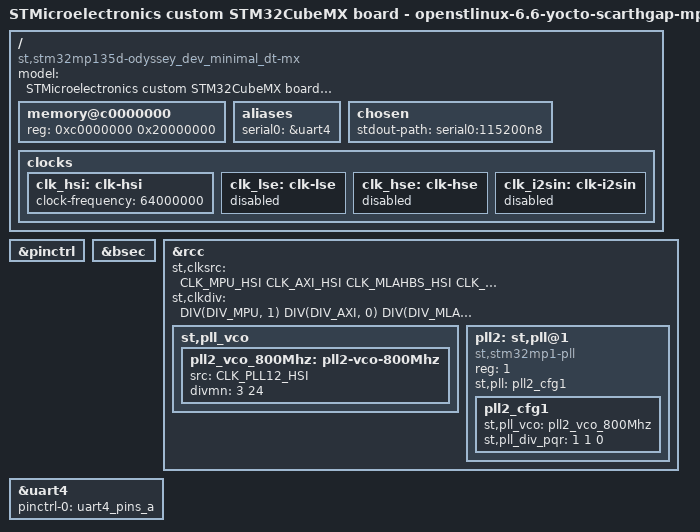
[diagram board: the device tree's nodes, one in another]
// SPDX-License-Identifier: (GPL-2.0+ OR BSD-3-Clause)
/*
 * Copyright (C) 2026, STMicroelectronics - All Rights Reserved
 * Author: STM32CubeMX code generation for STMicroelectronics.
 */

/* For more information on Device Tree configuration, please refer to
 * https://wiki.st.com/stm32mpu/wiki/Category:Device_tree_configuration
 */

/dts-v1/;

#include <dt-bindings/pinctrl/stm32-pinfunc.h>
#include <dt-bindings/clock/stm32mp13-clksrc.h>
#include "stm32mp13-mx.dtsi"

#include "stm32mp135.dtsi"
#include "stm32mp13xd.dtsi"
#include "stm32mp13-ddr.dtsi"

/* USER CODE BEGIN includes */
/* USER CODE END includes */

/ {
	model = "STMicroelectronics custom STM32CubeMX board - openstlinux-6.6-yocto-scarthgap-mpu-v26.02.18";
	compatible = "st,stm32mp135d-odyssey_dev_minimal_dt-mx", "st,stm32mp135";

	memory@c0000000 {
		device_type = "memory";
		reg = <0xc0000000 0x20000000>;

		/* USER CODE BEGIN memory */
		/* USER CODE END memory */
	};

	/* USER CODE BEGIN root */
	aliases {
		serial0 = &uart4;
	};

	chosen {
		stdout-path = "serial0:115200n8";
	};
	/* USER CODE END root */

	clocks {
		/* USER CODE BEGIN clocks */
		/* USER CODE END clocks */

		clk_hsi: clk-hsi {
			clock-frequency = <64000000>;

			/* USER CODE BEGIN clk_hsi */
			/* USER CODE END clk_hsi */
		};
		clk_lse: clk-lse {
			status = "disabled";

			/* USER CODE BEGIN clk_lse */
			/* USER CODE END clk_lse */
		};
		clk_hse: clk-hse {
			status = "disabled";

			/* USER CODE BEGIN clk_hse */
			/* USER CODE END clk_hse */
		};
		clk_i2sin: clk-i2sin {
			status = "disabled";

			/* USER CODE BEGIN clk_i2sin */
			/* USER CODE END clk_i2sin */
		};
	};

}; /*root*/

&pinctrl {
	/* USER CODE BEGIN pinctrl */
	/* USER CODE END pinctrl */
};

&bsec {
	status = "okay";

	/* USER CODE BEGIN bsec */
	/* USER CODE END bsec */
};

&rcc {
	status = "okay";
	st,clksrc = <
		CLK_MPU_HSI
		CLK_AXI_HSI
		CLK_MLAHBS_HSI
		CLK_CKPER_DISABLED
		CLK_STGEN_HSI
		CLK_UART4_PCLK1
	>;
	st,clkdiv = <
		DIV(DIV_MPU, 1)
		DIV(DIV_AXI, 0)
		DIV(DIV_MLAHB, 0)
		DIV(DIV_APB1, 0)
		DIV(DIV_APB2, 0)
		DIV(DIV_APB3, 0)
		DIV(DIV_APB4, 0)
		DIV(DIV_APB5, 0)
		DIV(DIV_APB6, 0)
	>;
	st,pll_vco {
		pll2_vco_800Mhz: pll2-vco-800Mhz {
			src = < CLK_PLL12_HSI >;
			divmn = < 3 24 >;
		};
		/* USER CODE BEGIN rcc_st-pll_vco */
		/* USER CODE END rcc_st-pll_vco */
	};

	pll2:st,pll@1 {
		compatible = "st,stm32mp1-pll";
		reg = <1>;

		st,pll = < &pll2_cfg1 >;

		pll2_cfg1: pll2_cfg1 {
			st,pll_vco = < &pll2_vco_800Mhz >;
			st,pll_div_pqr = < 1 1 0 >;
		};
		/* USER CODE BEGIN pll2 */
		/* USER CODE END pll2 */
	};

};

&uart4 {
	status = "okay";

	/* USER CODE BEGIN uart4 */
	pinctrl-0 = <&uart4_pins_a>;	
	/* USER CODE END uart4 */
};

/* USER CODE BEGIN addons */
/* USER CODE END addons */

